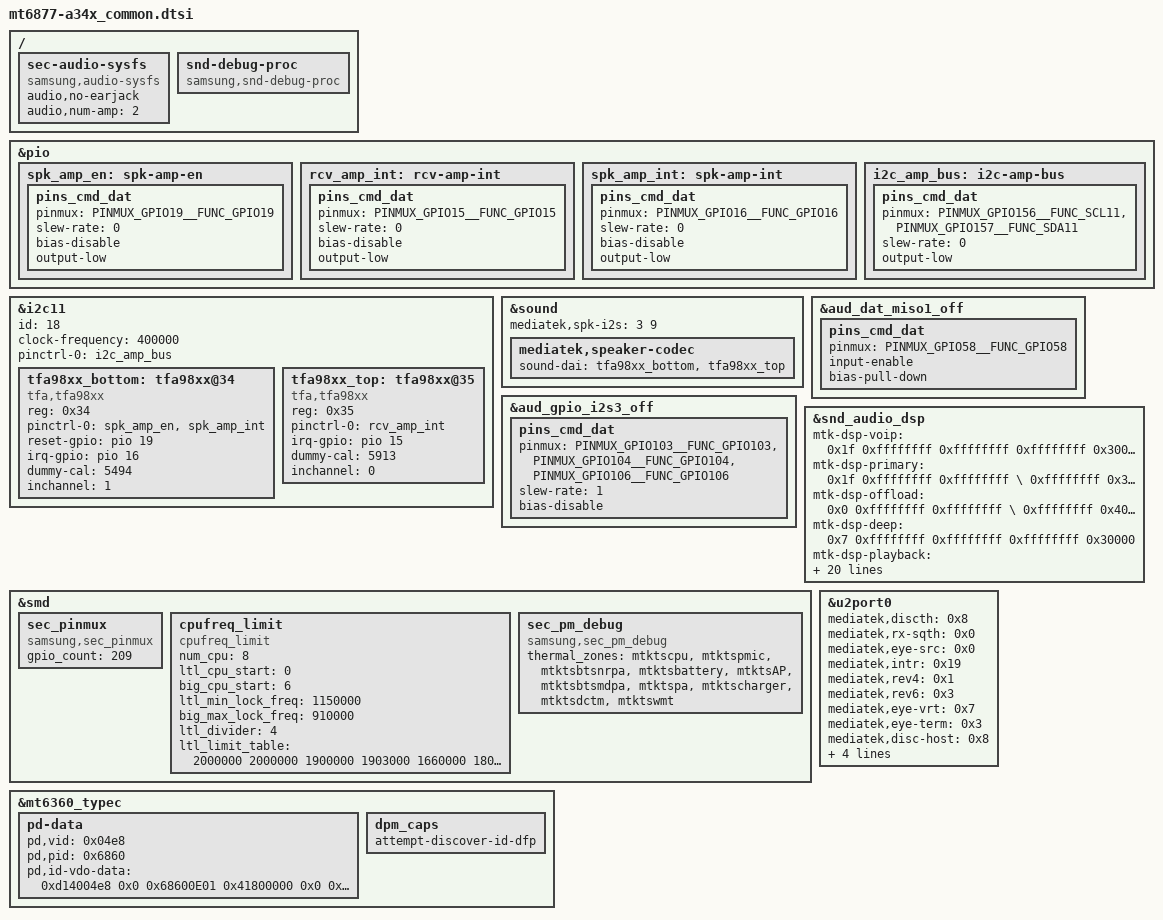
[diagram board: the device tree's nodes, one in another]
/* Generated by Samsung for MTK vendor board
 * If these files should be changed, then please make a sync with MTK
*/

/* Add Samsung configuration over here */
#include "display_lcd_a34x_common.dtsi"
#include "../mt6877_wakeup_cpu_allocator.dtsi"

/ {
	fragment@model {
		target-path = "/";
		__overlay__ {
			sec-audio-sysfs {
				compatible = "samsung,audio-sysfs";
				status = "okay";
				audio,no-earjack;
				audio,num-amp = <2>;
			};

			snd-debug-proc {
				compatible = "samsung,snd-debug-proc";
				status = "okay";
			};
		};
	};
};

&pio {
	spk_amp_en: spk-amp-en {
		pins_cmd_dat {
			pinmux = <PINMUX_GPIO19__FUNC_GPIO19>;
			slew-rate = <0>;
			bias-disable;
			output-low;
		};
	};

	rcv_amp_int: rcv-amp-int {
		pins_cmd_dat {
			pinmux = <PINMUX_GPIO15__FUNC_GPIO15>;
			slew-rate = <0>;
			bias-disable;
			output-low;
		};
	};

	spk_amp_int: spk-amp-int {
		pins_cmd_dat {
			pinmux = <PINMUX_GPIO16__FUNC_GPIO16>;
			slew-rate = <0>;
			bias-disable;
			output-low;
		};
	};

	i2c_amp_bus: i2c-amp-bus {
		pins_cmd_dat {
			pinmux = <PINMUX_GPIO156__FUNC_SCL11>,
				<PINMUX_GPIO157__FUNC_SDA11>;
			slew-rate = <0>;
			output-low;
		};
	};
};

&i2c11 {
	status = "okay";
	id = <18>;
	clock-frequency = <400000>;
	#address-cells = <1>;
	#size-cells = <0>;

	pinctrl-names = "default";
	pinctrl-0 = <&i2c_amp_bus>;

	tfa98xx_bottom: tfa98xx@34 {
		#sound-dai-cells = <0>;
		compatible = "tfa,tfa98xx";
		reg = <0x34>;

		pinctrl-names = "default";
		pinctrl-0 = <&spk_amp_en &spk_amp_int>;

		reset-gpio = <&pio 19  0>;
		irq-gpio = <&pio 16 0>;

		dummy-cal = <5494>;
		inchannel = <1>; /*right*/
	};

	tfa98xx_top: tfa98xx@35 {
		#sound-dai-cells = <0>;
		compatible = "tfa,tfa98xx";
		reg = <0x35>;

		pinctrl-names = "default";
		pinctrl-0 = <&rcv_amp_int>;

		irq-gpio = <&pio 15 0>;

		dummy-cal = <5913>;
		inchannel = <0>; /*left*/
	};
};

&sound {
	mediatek,spk-i2s = <3 9>;
	mediatek,speaker-codec {
		#sound-dai-cells = <2>;
		sound-dai = <&tfa98xx_bottom &tfa98xx_top>;
	};
};

&aud_dat_miso1_off {
	pins_cmd_dat {
		pinmux = <PINMUX_GPIO58__FUNC_GPIO58>;
		input-enable;
		bias-pull-down;
	};
};

&aud_gpio_i2s3_off {
	pins_cmd_dat {
		pinmux = <PINMUX_GPIO103__FUNC_GPIO103>,
			 <PINMUX_GPIO104__FUNC_GPIO104>,
			 <PINMUX_GPIO106__FUNC_GPIO106>;
		slew-rate = <1>;
		bias-disable;
	};
};

&snd_audio_dsp {
	mtk-dsp-voip = <0x1f 0xffffffff 0xffffffff 0xffffffff 0x30000>;
	mtk-dsp-primary = <0x1f 0xffffffff 0xffffffff \
			   0xffffffff 0x30000>;
	mtk-dsp-offload = <0x0 0xffffffff 0xffffffff \
			   0xffffffff 0x400000>;
	mtk-dsp-deep = <0x7 0xffffffff 0xffffffff 0xffffffff 0x30000>;
	mtk-dsp-playback = <0x1 0x4 0xffffffff 0x14 0x30000>;
	mtk-dsp-music = <0x1 0xffffffff 0xffffffff 0xffffffff 0x0>;
	mtk-dsp-capture1 = <0x1 0xffffffff 0xd 0x13 0x20000>;
	mtk-dsp-a2dp = <0x1 0xffffffff 0xffffffff 0xffffffff 0x40000>;
	mtk-dsp-dataprovider = <0x0 0xffffffff 0xf 0xffffffff 0x30000>;
	mtk-dsp-call-final = <0x5 0x4 0x10 0x14 0x18000>;
	mtk-dsp-fast = <0x5 0xffffffff 0xffffffff 0xffffffff 0x5000>;
	mtk-dsp-ktv = <0x1 0x8 0x12 0xffffffff 0x10000>;
	mtk-dsp-capture-raw = <0x0 0xffffffff 0xffffffff 0xffffffff 0x20000>;
	mtk-dsp-fm = <0x1 0xffffffff 0x10 0xffffffff 0x10000>;
	mtk-dsp-ver = <0x1>;
	swdsp-smartpa-process-enable = <0x5>;
	mtk-dsp-mem-afe = <0x1 0x40000>; /* always enable */
};

&smd {
	sec_pinmux {
		status = "okay";
		compatible = "samsung,sec_pinmux";
		gpio_count = <209>;
	};

	cpufreq_limit {
		status = "okay";
		compatible = "cpufreq_limit";

		num_cpu = <8>;
		ltl_cpu_start = <0>;
		big_cpu_start = <6>;
		ltl_min_lock_freq = <1150000>;
		big_max_lock_freq = <910000>;
		ltl_divider = <4>;
		ltl_limit_table = <
			2000000	2000000
			1900000	1903000
			1660000	1800000
			1540000	1703000
			650000	1600000
		>;
	};

	sec_pm_debug {
	status = "okay";
	compatible = "samsung,sec_pm_debug";

	thermal_zones = "mtktscpu", "mtktspmic", "mtktsbtsnrpa", "mtktsbattery",
					"mtktsAP", "mtktsbtsmdpa", "mtktspa", "mtktscharger",
					"mtktsdctm", "mtktswmt";
	};
};

&mt6360_typec {
	pd-data {
		pd,vid = <0x04e8>;
		pd,pid = <0x6860>;
		pd,id-vdo-data = <0xd14004e8 0x0 0x68600E01
				 0x41800000 0x0 0x21800000>;
	};

	dpm_caps {
		attempt-discover-id-dfp;
	};
};

&u2port0 {
	mediatek,discth = <0x8>;
	mediatek,rx-sqth = <0x0>;
	mediatek,eye-src = <0x0>;
	mediatek,intr = <0x19>;
	mediatek,rev4 = <0x1>;
	mediatek,rev6 = <0x3>;
	mediatek,eye-vrt = <0x7>;
	mediatek,eye-term = <0x3>;
	mediatek,disc-host = <0x8>;
	mediatek,eye-src-host = <0x0>;
	mediatek,eye-vrt-host = <0x7>;
	mediatek,eye-term-host = <0x3>;
	mediatek,rev6-host = <0x3>;
};
